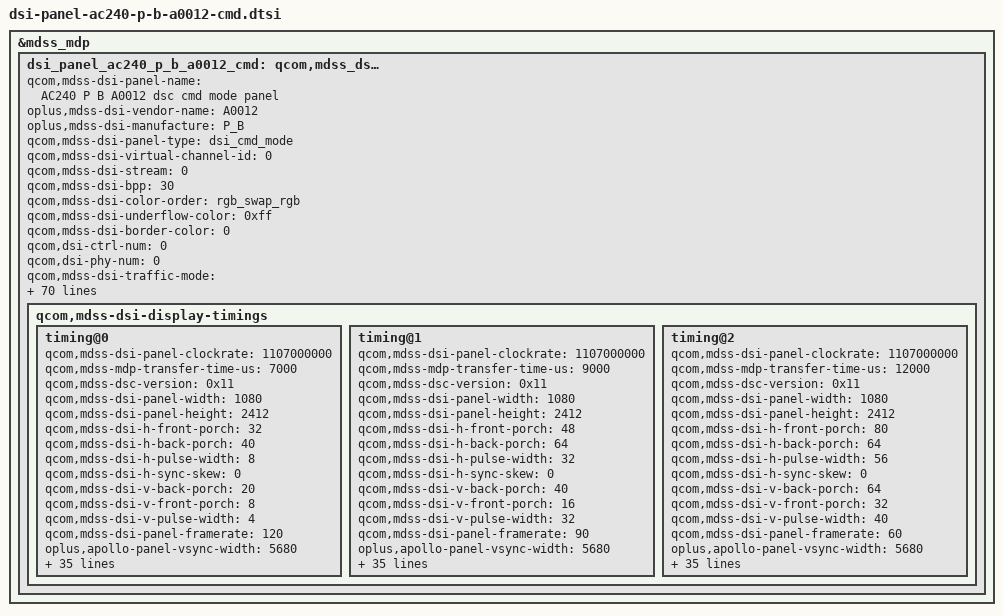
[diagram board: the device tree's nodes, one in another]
&mdss_mdp {
	dsi_panel_ac240_p_b_a0012_cmd: qcom,mdss_dsi_panel_ac240_p_b_a0012_cmd {
		qcom,mdss-dsi-panel-name = "AC240 P B A0012 dsc cmd mode panel";
		oplus,mdss-dsi-vendor-name = "A0012";
		oplus,mdss-dsi-manufacture = "P_B";
		qcom,mdss-dsi-panel-type = "dsi_cmd_mode";
		qcom,mdss-dsi-virtual-channel-id = <0>;
		qcom,mdss-dsi-stream = <0>;
		qcom,mdss-dsi-bpp = <30>;
		qcom,mdss-dsi-color-order = "rgb_swap_rgb";
		qcom,mdss-dsi-underflow-color = <0xff>;
		qcom,mdss-dsi-border-color = <0>;
		qcom,dsi-ctrl-num = <0>;
		qcom,dsi-phy-num = <0>;
		qcom,mdss-dsi-traffic-mode = "non_burst_sync_event";
		qcom,mdss-dsi-lane-map = "lane_map_0123";
		qcom,mdss-dsi-bllp-eof-power-mode;
		qcom,mdss-dsi-bllp-power-mode;
		qcom,mdss-dsi-lane-0-state;
		qcom,mdss-dsi-lane-1-state;
		qcom,mdss-dsi-lane-2-state;
		qcom,mdss-dsi-lane-3-state;
		qcom,mdss-dsi-dma-trigger = "trigger_sw";
		qcom,mdss-dsi-mdp-trigger = "none";
		qcom,mdss-dsi-bl-inverted-dbv;
		qcom,mdss-dsi-reset-sequence = <1 10>, <0 10>, <1 10>;
		qcom,mdss-dsi-te-pin-select = <1>;
		qcom,mdss-dsi-te-dcs-command = <1>;
		qcom,mdss-dsi-te-check-enable;
		qcom,mdss-dsi-te-using-te-pin;
		qcom,mdss-dsi-wr-mem-start = <0x2c>;
		qcom,mdss-dsi-wr-mem-continue = <0x3c>;
		qcom,mdss-dsi-panel-hdr-enabled;
		qcom,mdss-dsi-panel-hdr-color-primaries = <15000 15500 34000
			16000 13250 34500 7500 3000>;
		qcom,mdss-dsi-panel-peak-brightness = <4300000>;
		qcom,mdss-dsi-panel-blackness-level = <1023>;
		qcom,mdss-pan-physical-width-dimension = <70>;
		qcom,mdss-pan-physical-height-dimension = <155>;
		qcom,bl-update-flag = "delay_until_first_frame";

		qcom,mdss-dsi-display-timings {
			timing@0{
				qcom,mdss-dsi-panel-clockrate = <1107000000>;
				qcom,mdss-mdp-transfer-time-us = <7000>;
				qcom,mdss-dsc-version = <0x11>;
				qcom,mdss-dsi-panel-width = <1080>;
				qcom,mdss-dsi-panel-height = <2412>;
				qcom,mdss-dsi-h-front-porch = <32>;
				qcom,mdss-dsi-h-back-porch = <40>;
				qcom,mdss-dsi-h-pulse-width = <8>;
				qcom,mdss-dsi-h-sync-skew = <0>;
				qcom,mdss-dsi-v-back-porch = <20>;
				qcom,mdss-dsi-v-front-porch = <8>;
				qcom,mdss-dsi-v-pulse-width = <4>;
				qcom,mdss-dsi-panel-framerate = <120>;
				/* Apollo vsync config, need to measure TE signal */
				oplus,apollo-panel-vsync-width = <5680>;
				oplus,apollo-panel-vsync-period = <16850>;

				/* ofp config */
				oplus,ofp-need-to-sync-data-in-aod-unlocking;
				oplus,ofp-aod-off-insert-black-frame = <1>;
				oplus,ofp-aod-off-black-frame-total-time = <42>;
				oplus,ofp-need-to-separate-backlight;
				oplus,ofp-backlight-on-period = <1>;

				qcom,mdss-dsi-on-command = [
					/* NVM not reload */
					39 01 00 00 00 00 04 FF 78 38 08
					15 01 00 00 00 00 02 45 4C
					/* Frame Rate 120Hz */
					39 01 00 00 00 00 04 FF 78 38 02
					15 01 00 00 00 00 02 38 11
					/* DSC Setting(10bit_3.75X) */
					39 01 00 00 00 00 04 FF 78 38 07
					15 01 00 00 00 00 02 29 01
					39 01 00 00 00 00 64 20 00 00 00 00 00 11 00 00 ab 30 80 09 6c 04 38 00 0c 02 1c 02 1c 02 00 02 0e 00 20 01 1f 00 07 00 0c 08 bb 08 7a 18 00 10 f0 07 10 20 00 06 0f 0f 33 0e 1c 2a 38 46 54 62 69 70 77 79 7b 7d 7e 02 02 22 00 2a 40 2a be 3a fc 3a fa 3a f8 3b 38 3b 78 3b b6 4b b6 4b f4 4b f4 6c 34 84 74 00 00 00 00 00 00
					/* TE ON */
					39 01 00 00 00 00 04 FF 78 38 00
					15 01 00 00 00 00 02 35 00
					/* Dimming Setting */
					15 01 00 00 00 00 02 53 20
					/* IR IP ON */
					15 01 00 00 00 00 02 95 10
					39 01 00 00 00 00 04 FF 78 38 00
					/* Sleep out */
					15 01 00 00 00 00 02 11 00
					39 01 00 00 00 00 04 FF 78 38 05
					15 01 00 00 00 00 02 5B 42
					15 01 00 00 00 00 02 09 58
					15 01 00 00 00 00 02 11 05
					15 01 00 00 00 00 02 5C 46
					39 01 00 00 00 00 04 FF 78 38 00
					39 01 00 00 78 00 03 51 00 00
					/* OSC 3.10% */
					39 01 00 00 00 00 04 FF 78 38 0F
					15 01 00 00 00 00 02 6B 87
					15 01 00 00 00 00 02 6F 07
					/* ESD Check */
					39 01 00 00 00 00 04 FF 78 38 08
					15 01 00 00 00 00 02 57 25
					39 01 00 00 00 00 04 FF 78 38 06
					15 01 00 00 00 00 02 C6 01
					39 01 00 00 00 00 04 FF 78 38 00
					/* Display On */
					15 01 00 00 14 00 02 29 00
				];
				qcom,mdss-dsi-timing-switch-command = [
					/* 120hz Transition */
					39 00 00 00 00 00 04 FF 78 38 02
					39 00 00 00 00 00 02 38 11
					39 01 00 00 00 00 04 FF 78 38 00
				];
				qcom,mdss-dsi-off-command = [
					05 01 00 00 1A 00 01 28
					05 01 00 00 78 00 01 10
				];
				qcom,dsi-panel-date-switch-command = [
					/*read panel info switch page 00*/
					39 01 00 00 00 00 04 FF 78 38 0F
				];
				qcom,mdss-dsi-default-switch-page-command = [
					/*switch default page*/
					39 01 00 00 00 00 04 FF 78 38 00
				];
				qcom,mdss-dsi-timing-switch-command-state = "dsi_lp_mode";
				qcom,mdss-dsi-on-command-state = "dsi_lp_mode";
				qcom,mdss-dsi-off-command-state = "dsi_lp_mode";
				qcom,dsi-panel-date-switch-command-state = "dsi_lp_mode";
				qcom,mdss-dsi-default-switch-page-command-state = "dsi_lp_mode";
				qcom,compression-mode = "dsc";
				qcom,mdss-dsc-slice-height = <12>;
				qcom,mdss-dsc-slice-width = <540>;
				qcom,mdss-dsc-slice-per-pkt = <2>;
				qcom,mdss-dsc-bit-per-component = <10>;
				qcom,mdss-dsc-bit-per-pixel = <8>;
				qcom,mdss-dsc-block-prediction-enable;
			};
			timing@1{
				qcom,mdss-dsi-panel-clockrate = <1107000000>;
				qcom,mdss-mdp-transfer-time-us = <9000>;
				qcom,mdss-dsc-version = <0x11>;
				qcom,mdss-dsi-panel-width = <1080>;
				qcom,mdss-dsi-panel-height = <2412>;
				qcom,mdss-dsi-h-front-porch = <48>;
				qcom,mdss-dsi-h-back-porch = <64>;
				qcom,mdss-dsi-h-pulse-width = <32>;
				qcom,mdss-dsi-h-sync-skew = <0>;
				qcom,mdss-dsi-v-back-porch = <40>;
				qcom,mdss-dsi-v-front-porch = <16>;
				qcom,mdss-dsi-v-pulse-width = <32>;
				qcom,mdss-dsi-panel-framerate = <90>;
				/* Apollo vsync config, need to measure TE signal */
				oplus,apollo-panel-vsync-width = <5680>;
				oplus,apollo-panel-vsync-period = <16850>;

				/* ofp config */
				oplus,ofp-need-to-sync-data-in-aod-unlocking;
				oplus,ofp-aod-off-insert-black-frame = <1>;
				oplus,ofp-aod-off-black-frame-total-time = <45>;
				oplus,ofp-need-to-separate-backlight;
				oplus,ofp-backlight-on-period = <1>;

				qcom,mdss-dsi-on-command = [
					/* NVM not reload */
					39 01 00 00 00 00 04 FF 78 38 08
					15 01 00 00 00 00 02 45 4C
					/* Frame Rate 90Hz */
					39 01 00 00 00 00 04 FF 78 38 02
					15 01 00 00 00 00 02 38 12
					/* DSC Setting(10bit_3.75X) */
					39 01 00 00 00 00 04 FF 78 38 07
					15 01 00 00 00 00 02 29 01
					39 01 00 00 00 00 64 20 00 00 00 00 00 11 00 00 ab 30 80 09 6c 04 38 00 0c 02 1c 02 1c 02 00 02 0e 00 20 01 1f 00 07 00 0c 08 bb 08 7a 18 00 10 f0 07 10 20 00 06 0f 0f 33 0e 1c 2a 38 46 54 62 69 70 77 79 7b 7d 7e 02 02 22 00 2a 40 2a be 3a fc 3a fa 3a f8 3b 38 3b 78 3b b6 4b b6 4b f4 4b f4 6c 34 84 74 00 00 00 00 00 00
					/* TE ON */
					39 01 00 00 00 00 04 FF 78 38 00
					15 01 00 00 00 00 02 35 00
					/* Dimming Setting */
					15 01 00 00 00 00 02 53 20
					/* IR IP ON */
					15 01 00 00 00 00 02 95 10
					39 01 00 00 00 00 04 FF 78 38 00
					/* Sleep out */
					15 01 00 00 00 00 02 11 00
					39 01 00 00 00 00 04 FF 78 38 05
					15 01 00 00 00 00 02 5B 42
					15 01 00 00 00 00 02 09 58
					15 01 00 00 00 00 02 11 05
					15 01 00 00 00 00 02 5C 46
					39 01 00 00 00 00 04 FF 78 38 00
					39 01 00 00 78 00 03 51 00 00
					/* OSC 3.10% */
					39 01 00 00 00 00 04 FF 78 38 0F
					15 01 00 00 00 00 02 6B 87
					15 01 00 00 00 00 02 6F 07
					/* ESD Check */
					39 01 00 00 00 00 04 FF 78 38 08
					15 01 00 00 00 00 02 57 25
					39 01 00 00 00 00 04 FF 78 38 06
					15 01 00 00 00 00 02 C6 01
					39 01 00 00 00 00 04 FF 78 38 00
					/* Display On */
					15 01 00 00 14 00 02 29 00
				];
				qcom,mdss-dsi-off-command = [
					05 01 00 00 1A 00 01 28
					05 01 00 00 78 00 01 10
				];
				qcom,mdss-dsi-timing-switch-command = [
					/* 90hz Transition */
					39 00 00 00 00 00 04 FF 78 38 02
					39 00 00 00 00 00 02 38 12
					39 01 00 00 00 00 04 FF 78 38 00
				];
				qcom,dsi-panel-date-switch-command = [
					/*read panel info switch page 00*/
					39 01 00 00 00 00 04 FF 78 38 0F
				];
				qcom,mdss-dsi-default-switch-page-command = [
					/*switch default page*/
					39 01 00 00 00 00 04 FF 78 38 00
				];
				qcom,mdss-dsi-timing-switch-command-state = "dsi_lp_mode";
				qcom,mdss-dsi-on-command-state = "dsi_lp_mode";
				qcom,mdss-dsi-off-command-state = "dsi_lp_mode";
				qcom,dsi-panel-date-switch-command-state = "dsi_lp_mode";
				qcom,mdss-dsi-default-switch-page-command-state = "dsi_lp_mode";
				qcom,compression-mode = "dsc";
				qcom,mdss-dsc-slice-height = <12>;
				qcom,mdss-dsc-slice-width = <540>;
				qcom,mdss-dsc-slice-per-pkt = <2>;
				qcom,mdss-dsc-bit-per-component = <10>;
				qcom,mdss-dsc-bit-per-pixel = <8>;
				qcom,mdss-dsc-block-prediction-enable;
			};
			timing@2{
				qcom,mdss-dsi-panel-clockrate = <1107000000>;
				qcom,mdss-mdp-transfer-time-us = <12000>;
				qcom,mdss-dsc-version = <0x11>;
				qcom,mdss-dsi-panel-width = <1080>;
				qcom,mdss-dsi-panel-height = <2412>;
				qcom,mdss-dsi-h-front-porch = <80>;
				qcom,mdss-dsi-h-back-porch = <64>;
				qcom,mdss-dsi-h-pulse-width = <56>;
				qcom,mdss-dsi-h-sync-skew = <0>;
				qcom,mdss-dsi-v-back-porch = <64>;
				qcom,mdss-dsi-v-front-porch = <32>;
				qcom,mdss-dsi-v-pulse-width = <40>;
				qcom,mdss-dsi-panel-framerate = <60>;
				/* Apollo vsync config, need to measure TE signal */
				oplus,apollo-panel-vsync-width = <5680>;
				oplus,apollo-panel-vsync-period = <16850>;

				/* ofp config */
				oplus,ofp-need-to-sync-data-in-aod-unlocking;
				oplus,ofp-aod-off-insert-black-frame = <2>;
				oplus,ofp-aod-off-black-frame-total-time = <59>;
				oplus,ofp-need-to-separate-backlight;
				oplus,ofp-backlight-on-period = <1>;

				qcom,mdss-dsi-on-command = [
					/* NVM not reload */
					39 01 00 00 00 00 04 FF 78 38 08
					15 01 00 00 00 00 02 45 4C
					/* Frame Rate 60Hz */
					39 01 00 00 00 00 04 FF 78 38 02
					15 01 00 00 00 00 02 38 13
					/* DSC Setting(10bit_3.75X) */
					39 01 00 00 00 00 04 FF 78 38 07
					15 01 00 00 00 00 02 29 01
					39 01 00 00 00 00 64 20 00 00 00 00 00 11 00 00 ab 30 80 09 6c 04 38 00 0c 02 1c 02 1c 02 00 02 0e 00 20 01 1f 00 07 00 0c 08 bb 08 7a 18 00 10 f0 07 10 20 00 06 0f 0f 33 0e 1c 2a 38 46 54 62 69 70 77 79 7b 7d 7e 02 02 22 00 2a 40 2a be 3a fc 3a fa 3a f8 3b 38 3b 78 3b b6 4b b6 4b f4 4b f4 6c 34 84 74 00 00 00 00 00 00
					/* TE ON */
					39 01 00 00 00 00 04 FF 78 38 00
					15 01 00 00 00 00 02 35 00
					/* Dimming Setting */
					15 01 00 00 00 00 02 53 20
					/* IR IP ON */
					15 01 00 00 00 00 02 95 10
					39 01 00 00 00 00 04 FF 78 38 00
					/* Sleep out */
					15 01 00 00 00 00 02 11 00
					39 01 00 00 00 00 04 FF 78 38 05
					15 01 00 00 00 00 02 5B 42
					15 01 00 00 00 00 02 09 58
					15 01 00 00 00 00 02 11 05
					15 01 00 00 00 00 02 5C 46
					39 01 00 00 00 00 04 FF 78 38 00
					39 01 00 00 78 00 03 51 00 00
					/* OSC 3.10% */
					39 01 00 00 00 00 04 FF 78 38 0F
					15 01 00 00 00 00 02 6B 87
					15 01 00 00 00 00 02 6F 07
					/* ESD Check */
					39 01 00 00 00 00 04 FF 78 38 08
					15 01 00 00 00 00 02 57 25
					39 01 00 00 00 00 04 FF 78 38 06
					15 01 00 00 00 00 02 C6 01
					39 01 00 00 00 00 04 FF 78 38 00
					/* Display On */
					15 01 00 00 14 00 02 29 00
				];
				qcom,mdss-dsi-timing-switch-command = [
					/* 60hz Transition */
					39 00 00 00 00 00 04 FF 78 38 02
					39 00 00 00 00 00 02 38 13
					39 01 00 00 00 00 04 FF 78 38 00
				];
				qcom,mdss-dsi-off-command = [
					05 01 00 00 1A 00 01 28
					05 01 00 00 78 00 01 10
				];
				qcom,dsi-panel-date-switch-command = [
					/*read panel info switch page 00*/
					39 01 00 00 00 00 04 FF 78 38 0F
				];
				qcom,mdss-dsi-default-switch-page-command = [
					/*switch default page*/
					39 01 00 00 00 00 04 FF 78 38 00
				];
				qcom,mdss-dsi-timing-switch-command-state = "dsi_lp_mode";
				qcom,mdss-dsi-on-command-state = "dsi_lp_mode";
				qcom,mdss-dsi-off-command-state = "dsi_lp_mode";
				qcom,dsi-panel-date-switch-command-state = "dsi_lp_mode";
				qcom,mdss-dsi-default-switch-page-command-state = "dsi_lp_mode";
				qcom,compression-mode = "dsc";
				qcom,mdss-dsc-slice-height = <12>;
				qcom,mdss-dsc-slice-width = <540>;
				qcom,mdss-dsc-slice-per-pkt = <2>;
				qcom,mdss-dsc-bit-per-component = <10>;
				qcom,mdss-dsc-bit-per-pixel = <8>;
				qcom,mdss-dsc-block-prediction-enable;
			};
		};
	};
};

&dsi_panel_ac240_p_b_a0012_cmd {
	qcom,panel-supply-entries = <&Alpha_M_dsi_panel_pwr_supply_oled>;
	qcom,mdss-dsi-bl-pmic-control-type = "bl_ctrl_dcs";
	qcom,mdss-dsi-bl-min-level = <1>;
	qcom,mdss-dsi-bl-max-level = <4094>;
	qcom,mdss-brightness-max-level = <4094>;
	qcom,mdss-dsi-bl-hbm-min-level = <3327>;
	oplus,dsi-bl-normal-max-level = <3515>;
	oplus,dsi-brightness-normal-max-level = <3515>;
	oplus,dsi-brightness-default-level = <1843>;
	qcom,platform-te-gpio = <&tlmm 99 0>;
	qcom,platform-reset-gpio = <&tlmm 98 0>;


	/* power config */
	qcom,panel_voltage_vddr_name = "vci";
	qcom,panel_voltage_vddr = <1 3000000 3200000 3300000>;
	qcom,panel_voltage_vddr_name = "vdd";
	qcom,panel_voltage_vddr = <1 1230000 1230000 1230000>;

	oplus,panel-power-on-sequence = "1", "vdd", "3", "vci", "3";
	oplus,panel-power-off-sequence = "1", "vdd", "3", "vci", "3";

	qcom,esd-check-enabled;
	qcom,mdss-dsi-panel-status-check-mode = "reg_read";
	qcom,mdss-dsi-panel-status-command = [
		06 01 00 01 00 00 01 0A
	];
	qcom,mdss-dsi-panel-status-command-state = "dsi_lp_mode";
	qcom,mdss-dsi-panel-status-value = <0x9C>;
	qcom,mdss-dsi-panel-status-read-length = <1>;
	oplus,mdss-dsi-panel-status-match-modes = <0x00000000>;

	qcom,ulps-enabled;
	qcom,suspend-ulps-enabled;
	qcom,dsi-select-clocks = "pll_byte_clk0", "pll_dsi_clk0";


	/* serial-number */
	oplus,dsi-serial-number-enabled;
	oplus,dsi-serial-number-index= <0>;
	oplus,dsi-serial-number-switch-page;
	oplus,dsi-serial-number-multi-reg;
	oplus,dsi-serial-number-multi-regs = [00 01 02 03 04 05 06];

	qcom,mdss-dsi-display-timings {
		/* 120hz 553.5mhz */
		timing@0{
			qcom,mdss-dsi-panel-phy-timings = [00 24 0A 0A 1A 18 0A 0A 09 02 04 00 1E 0F];
			qcom,display-topology = <1 1 1>;
			qcom,default-topology-index = <0>;
		};
		/* 90hz 553.5mhz */
		timing@1{
			qcom,mdss-dsi-panel-phy-timings = [00 24 0A 0A 1A 18 0A 0A 09 02 04 00 1E 0F];
			qcom,display-topology = <1 1 1>;
			qcom,default-topology-index = <0>;
		};
		/* 60hz 553.5mhz */
		timing@2{
			qcom,mdss-dsi-panel-phy-timings = [00 24 0A 0A 1A 18 0A 0A 09 02 04 00 1E 0F];
			qcom,display-topology = <1 1 1>;
			qcom,default-topology-index = <0>;
		};
	};
};

&dsi_panel_ac240_p_b_a0012_cmd {
	qcom,panel_voltage_vddi_name = "vddio";
	qcom,panel_voltage_vddi = <1 1700000 1800000 1900000>;
	qcom,panel_voltage_vddr_name = "vci";
	qcom,panel_voltage_vddr = <1 3000000 3200000 3300000>;
};
